VERSION ""

NS_ :

BS_:

BU_:

BO_ 257 state: 1 Vector__XXX
 SG_ system_state : 0|8@1+ (1,0) [0|255] "" Vector__XXX

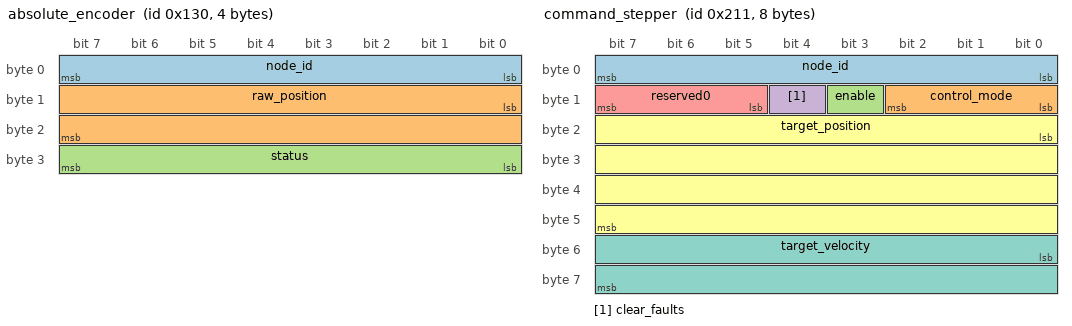
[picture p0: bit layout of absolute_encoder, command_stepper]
BO_ 304 absolute_encoder: 4 Vector__XXX
 SG_ node_id : 0|8@1+ (1,0) [0|255] "" Vector__XXX
 SG_ raw_position : 8|16@1+ (1,0) [0|16383] "count" Vector__XXX
 SG_ status : 24|8@1+ (1,0) [0|255] "" Vector__XXX

BO_ 529 command_stepper: 8 Vector__XXX
 SG_ node_id : 0|8@1+ (1,0) [0|255] "" Vector__XXX
 SG_ control_mode : 8|3@1+ (1,0) [0|7] "" Vector__XXX
 SG_ enable : 11|1@1+ (1,0) [0|1] "" Vector__XXX
 SG_ clear_faults : 12|1@1+ (1,0) [0|1] "" Vector__XXX
 SG_ reserved0 : 13|3@1+ (1,0) [0|7] "" Vector__XXX
 SG_ target_position : 16|32@1- (1,0) [-2147483648|2147483647] "ustep" Vector__XXX
 SG_ target_velocity : 48|16@1- (1,0) [-32768|32767] "ustep/s" Vector__XXX

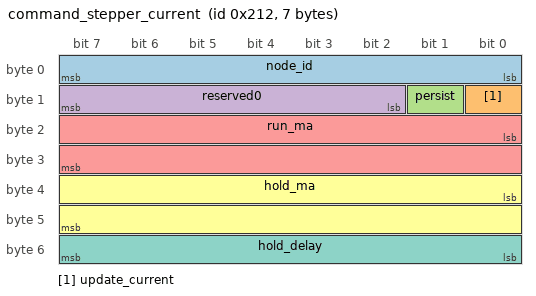
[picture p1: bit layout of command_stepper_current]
BO_ 530 command_stepper_current: 7 Vector__XXX
 SG_ node_id : 0|8@1+ (1,0) [0|255] "" Vector__XXX
 SG_ update_current : 8|1@1+ (1,0) [0|1] "" Vector__XXX
 SG_ persist : 9|1@1+ (1,0) [0|1] "" Vector__XXX
 SG_ reserved0 : 10|6@1+ (1,0) [0|63] "" Vector__XXX
 SG_ run_ma : 16|16@1+ (1,0) [0|3000] "mA" Vector__XXX
 SG_ hold_ma : 32|16@1+ (1,0) [0|3000] "mA" Vector__XXX
 SG_ hold_delay : 48|8@1+ (1,0) [0|255] "" Vector__XXX

CM_ BO_ 257 "State machine info";
BA_DEF_  "BusType" STRING ;
BA_DEF_DEF_  "BusType" "CAN";
